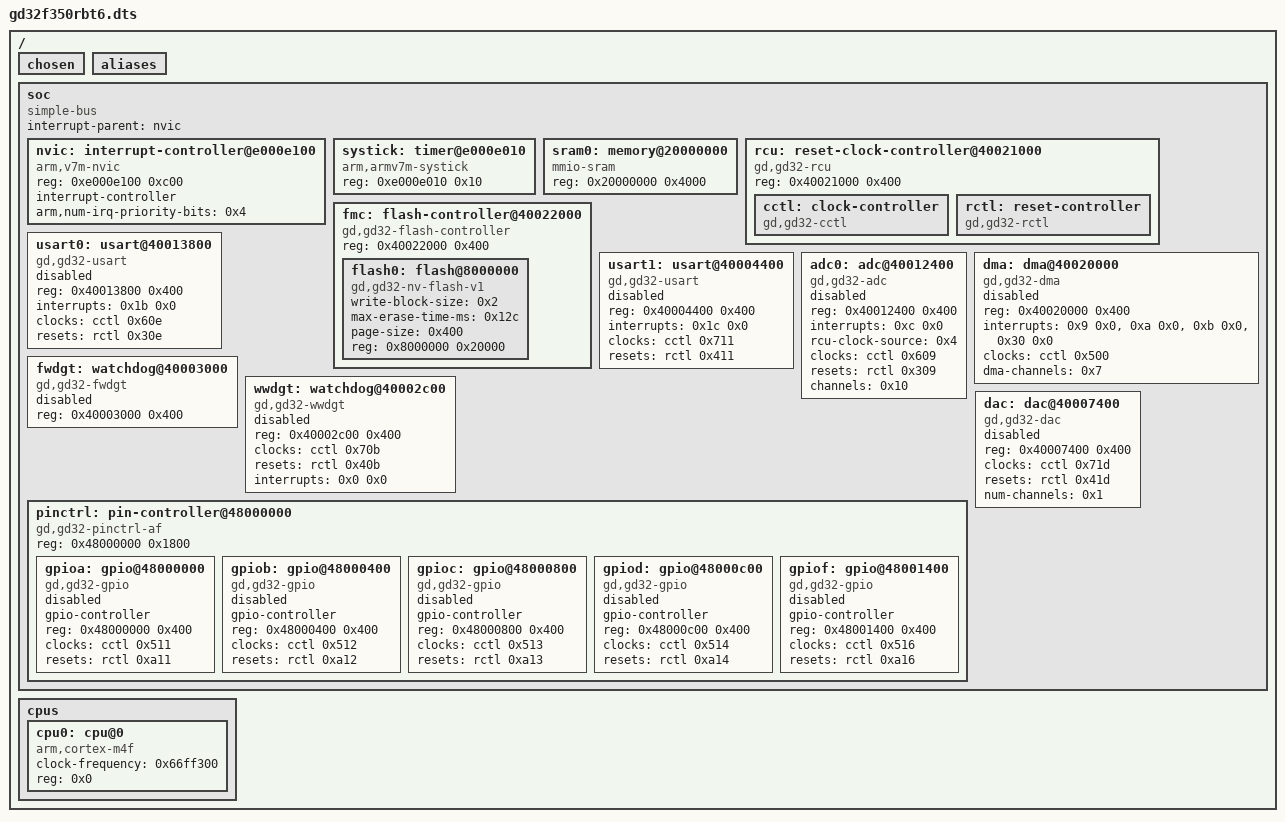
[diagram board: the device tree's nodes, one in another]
/dts-v1/;

/ {
	#address-cells = < 0x1 >;
	#size-cells = < 0x1 >;
	chosen {
	};
	aliases {
	};
	soc {
		#address-cells = < 0x1 >;
		#size-cells = < 0x1 >;
		compatible = "simple-bus";
		interrupt-parent = < &nvic >;
		ranges;
		nvic: interrupt-controller@e000e100 {
			#address-cells = < 0x1 >;
			compatible = "arm,v7m-nvic";
			reg = < 0xe000e100 0xc00 >;
			interrupt-controller;
			#interrupt-cells = < 0x2 >;
			arm,num-irq-priority-bits = < 0x4 >;
			phandle = < 0x1 >;
		};
		systick: timer@e000e010 {
			compatible = "arm,armv7m-systick";
			reg = < 0xe000e010 0x10 >;
		};
		sram0: memory@20000000 {
			compatible = "mmio-sram";
			reg = < 0x20000000 0x4000 >;
		};
		rcu: reset-clock-controller@40021000 {
			compatible = "gd,gd32-rcu";
			reg = < 0x40021000 0x400 >;
			status = "okay";
			cctl: clock-controller {
				compatible = "gd,gd32-cctl";
				#clock-cells = < 0x1 >;
				status = "okay";
				phandle = < 0x2 >;
			};
			rctl: reset-controller {
				compatible = "gd,gd32-rctl";
				#reset-cells = < 0x1 >;
				status = "okay";
				phandle = < 0x3 >;
			};
		};
		fmc: flash-controller@40022000 {
			compatible = "gd,gd32-flash-controller";
			reg = < 0x40022000 0x400 >;
			#address-cells = < 0x1 >;
			#size-cells = < 0x1 >;
			flash0: flash@8000000 {
				compatible = "gd,gd32-nv-flash-v1", "soc-nv-flash";
				write-block-size = < 0x2 >;
				max-erase-time-ms = < 0x12c >;
				page-size = < 0x400 >;
				reg = < 0x8000000 0x20000 >;
			};
		};
		usart0: usart@40013800 {
			compatible = "gd,gd32-usart";
			reg = < 0x40013800 0x400 >;
			interrupts = < 0x1b 0x0 >;
			clocks = < &cctl 0x60e >;
			resets = < &rctl 0x30e >;
			status = "disabled";
		};
		usart1: usart@40004400 {
			compatible = "gd,gd32-usart";
			reg = < 0x40004400 0x400 >;
			interrupts = < 0x1c 0x0 >;
			clocks = < &cctl 0x711 >;
			resets = < &rctl 0x411 >;
			status = "disabled";
		};
		adc0: adc@40012400 {
			compatible = "gd,gd32-adc";
			reg = < 0x40012400 0x400 >;
			interrupts = < 0xc 0x0 >;
			rcu-clock-source = < 0x4 >;
			clocks = < &cctl 0x609 >;
			resets = < &rctl 0x309 >;
			channels = < 0x10 >;
			status = "disabled";
			#io-channel-cells = < 0x1 >;
		};
		dma: dma@40020000 {
			compatible = "gd,gd32-dma";
			reg = < 0x40020000 0x400 >;
			interrupts = < 0x9 0x0 >, < 0xa 0x0 >, < 0xb 0x0 >, < 0x30 0x0 >;
			clocks = < &cctl 0x500 >;
			dma-channels = < 0x7 >;
			#dma-cells = < 0x2 >;
			status = "disabled";
		};
		fwdgt: watchdog@40003000 {
			compatible = "gd,gd32-fwdgt";
			reg = < 0x40003000 0x400 >;
			status = "disabled";
		};
		wwdgt: watchdog@40002c00 {
			compatible = "gd,gd32-wwdgt";
			reg = < 0x40002c00 0x400 >;
			clocks = < &cctl 0x70b >;
			resets = < &rctl 0x40b >;
			interrupts = < 0x0 0x0 >;
			status = "disabled";
		};
		pinctrl: pin-controller@48000000 {
			compatible = "gd,gd32-pinctrl-af";
			reg = < 0x48000000 0x1800 >;
			#address-cells = < 0x1 >;
			#size-cells = < 0x1 >;
			status = "okay";
			gpioa: gpio@48000000 {
				compatible = "gd,gd32-gpio";
				gpio-controller;
				#gpio-cells = < 0x2 >;
				reg = < 0x48000000 0x400 >;
				clocks = < &cctl 0x511 >;
				resets = < &rctl 0xa11 >;
				status = "disabled";
			};
			gpiob: gpio@48000400 {
				compatible = "gd,gd32-gpio";
				gpio-controller;
				#gpio-cells = < 0x2 >;
				reg = < 0x48000400 0x400 >;
				clocks = < &cctl 0x512 >;
				resets = < &rctl 0xa12 >;
				status = "disabled";
			};
			gpioc: gpio@48000800 {
				compatible = "gd,gd32-gpio";
				gpio-controller;
				#gpio-cells = < 0x2 >;
				reg = < 0x48000800 0x400 >;
				clocks = < &cctl 0x513 >;
				resets = < &rctl 0xa13 >;
				status = "disabled";
			};
			gpiod: gpio@48000c00 {
				compatible = "gd,gd32-gpio";
				gpio-controller;
				#gpio-cells = < 0x2 >;
				reg = < 0x48000c00 0x400 >;
				clocks = < &cctl 0x514 >;
				resets = < &rctl 0xa14 >;
				status = "disabled";
			};
			gpiof: gpio@48001400 {
				compatible = "gd,gd32-gpio";
				gpio-controller;
				#gpio-cells = < 0x2 >;
				reg = < 0x48001400 0x400 >;
				clocks = < &cctl 0x516 >;
				resets = < &rctl 0xa16 >;
				status = "disabled";
			};
		};
		dac: dac@40007400 {
			compatible = "gd,gd32-dac";
			reg = < 0x40007400 0x400 >;
			clocks = < &cctl 0x71d >;
			resets = < &rctl 0x41d >;
			num-channels = < 0x1 >;
			status = "disabled";
			#io-channel-cells = < 0x1 >;
		};
	};
	cpus {
		#address-cells = < 0x1 >;
		#size-cells = < 0x0 >;
		cpu0: cpu@0 {
			clock-frequency = < 0x66ff300 >;
			compatible = "arm,cortex-m4f";
			reg = < 0x0 >;
		};
	};
};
